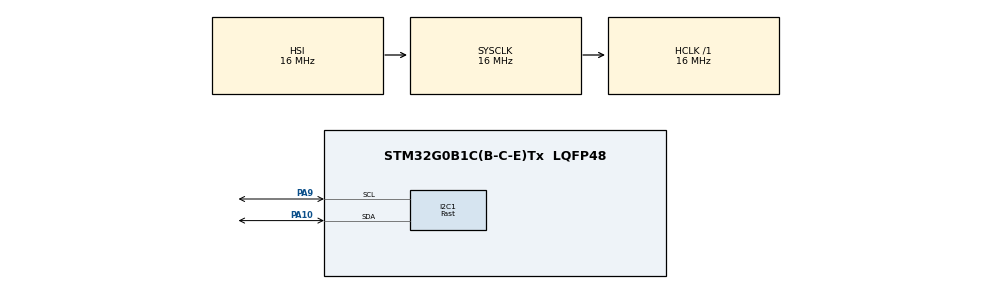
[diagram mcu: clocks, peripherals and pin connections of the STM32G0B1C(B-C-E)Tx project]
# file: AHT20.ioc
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Dma.I2C1_RX.0.Direction=DMA_PERIPH_TO_MEMORY
Dma.I2C1_RX.0.EventEnable=DISABLE
Dma.I2C1_RX.0.Instance=DMA1_Channel1
Dma.I2C1_RX.0.MemDataAlignment=DMA_MDATAALIGN_BYTE
Dma.I2C1_RX.0.MemInc=DMA_MINC_ENABLE
Dma.I2C1_RX.0.Mode=DMA_NORMAL
Dma.I2C1_RX.0.PeriphDataAlignment=DMA_PDATAALIGN_BYTE
Dma.I2C1_RX.0.PeriphInc=DMA_PINC_DISABLE
Dma.I2C1_RX.0.Polarity=HAL_DMAMUX_REQ_GEN_RISING
Dma.I2C1_RX.0.Priority=DMA_PRIORITY_LOW
Dma.I2C1_RX.0.RequestNumber=1
Dma.I2C1_RX.0.SignalID=NONE
Dma.I2C1_RX.0.SyncEnable=DISABLE
Dma.I2C1_RX.0.SyncPolarity=HAL_DMAMUX_SYNC_NO_EVENT
Dma.I2C1_RX.0.SyncRequestNumber=1
Dma.I2C1_RX.0.SyncSignalID=NONE
Dma.I2C1_TX.1.Direction=DMA_MEMORY_TO_PERIPH
Dma.I2C1_TX.1.EventEnable=DISABLE
Dma.I2C1_TX.1.Instance=DMA1_Channel2
Dma.I2C1_TX.1.MemDataAlignment=DMA_MDATAALIGN_BYTE
Dma.I2C1_TX.1.MemInc=DMA_MINC_ENABLE
Dma.I2C1_TX.1.Mode=DMA_NORMAL
Dma.I2C1_TX.1.PeriphDataAlignment=DMA_PDATAALIGN_BYTE
Dma.I2C1_TX.1.PeriphInc=DMA_PINC_DISABLE
Dma.I2C1_TX.1.Polarity=HAL_DMAMUX_REQ_GEN_RISING
Dma.I2C1_TX.1.Priority=DMA_PRIORITY_LOW
Dma.I2C1_TX.1.RequestNumber=1
Dma.I2C1_TX.1.SignalID=NONE
Dma.I2C1_TX.1.SyncEnable=DISABLE
Dma.I2C1_TX.1.SyncPolarity=HAL_DMAMUX_SYNC_NO_EVENT
Dma.I2C1_TX.1.SyncRequestNumber=1
Dma.I2C1_TX.1.SyncSignalID=NONE
Dma.Request0=I2C1_RX
Dma.Request1=I2C1_TX
FREERTOS.BinarySemaphores01=myBinarySem01,Static,myBinarySem01ControlBlock,Available
FREERTOS.Tasks01=defaultTask,24,128,StartDefaultTask,Default,NULL,Dynamic,NULL,NULL
FREERTOS.configENABLE_FPU=1
FREERTOS.configUSE_NEWLIB_REENTRANT=1
I2C1.I2C_Speed_Mode=I2C_Fast
I2C1.Timing=0x00300617
Mcu.Family=STM32G0
Mcu.Name=STM32G0B1C(B-C-E)Tx
Mcu.Package=LQFP48
NVIC.DMA1_Channel1_IRQn=true\:3\:0\:false\:false\:true\:true\:false\:true\:true
NVIC.DMA1_Channel2_3_IRQn=true\:3\:0\:false\:false\:true\:true\:false\:true\:true
NVIC.I2C1_IRQn=true\:3\:0\:false\:false\:true\:true\:true\:true\:true
PA10.GPIO_Pu=GPIO_PULLUP
PA10.Mode=I2C
PA10.Signal=I2C1_SDA
PA13.Mode=Serial_Wire
PA13.Signal=SYS_SWDIO
PA14-BOOT0.Mode=Serial_Wire
PA14-BOOT0.Signal=SYS_SWCLK
PA9.GPIO_Pu=GPIO_PULLUP
PA9.Mode=I2C
PA9.Signal=I2C1_SCL
ProjectManager.HeapSize=0x200
ProjectManager.StackSize=0x400
ProjectManager.TargetToolchain=STM32CubeIDE
RCC.AHBFreq_Value=16000000
RCC.CortexFreq_Value=16000000
RCC.EXTERNAL_CLOCK_VALUE=48000
RCC.HCLKFreq_Value=16000000
RCC.HSE_VALUE=8000000
RCC.HSI48_VALUE=48000000
RCC.HSI_VALUE=16000000
RCC.LSE_VALUE=32768
RCC.SYSCLKFreq_VALUE=16000000
RCC.USBFreq_Value=48000000
RCC.VCOOutputFreq_Value=128000000
VP_FREERTOS_VS_CMSIS_V2.Mode=CMSIS_V2
VP_SYS_VS_DBSignals.Mode=DisableDeadBatterySignals
board=custom

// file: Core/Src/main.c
/* USER CODE BEGIN Header */
/**
  ******************************************************************************
  * @file           : main.c
  * @brief          : Main program body
  ******************************************************************************
  * @attention
  *
  * Copyright (c) 2026 STMicroelectronics.
  * All rights reserved.
  *
  * This software is licensed under terms that can be found in the LICENSE file
  * in the root directory of this software component.
  * If no LICENSE file comes with this software, it is provided AS-IS.
  *
  ******************************************************************************
  */
/* USER CODE END Header */
#include "main.h"
#include "cmsis_os.h"
#include "dma.h"
#include "i2c.h"
#include "gpio.h"

void SystemClock_Config(void);
void MX_FREERTOS_Init(void);

int main(void)
{

  /* MCU Configuration--------------------------------------------------------*/

  /* Reset of all peripherals, Initializes the Flash interface and the Systick. */
  HAL_Init();

  /* Configure the system clock */
  SystemClock_Config();

  /* Initialize all configured peripherals */
  MX_GPIO_Init();
  MX_DMA_Init();
  MX_I2C1_Init();

  /* Init scheduler */
  osKernelInitialize();  /* Call init function for freertos objects (in cmsis_os2.c) */
  MX_FREERTOS_Init();

  /* Start scheduler */
  osKernelStart();

  /* We should never get here as control is now taken by the scheduler */

  /* Infinite loop */
  while (1)
  {

  }
}

void SystemClock_Config(void)
{
  RCC_OscInitTypeDef RCC_OscInitStruct = {0};
  RCC_ClkInitTypeDef RCC_ClkInitStruct = {0};

  /** Configure the main internal regulator output voltage
  */
  HAL_PWREx_ControlVoltageScaling(PWR_REGULATOR_VOLTAGE_SCALE1);

  /** Initializes the RCC Oscillators according to the specified parameters
  * in the RCC_OscInitTypeDef structure.
  */
  RCC_OscInitStruct.OscillatorType = RCC_OSCILLATORTYPE_HSI;
  RCC_OscInitStruct.HSIState = RCC_HSI_ON;
  RCC_OscInitStruct.HSIDiv = RCC_HSI_DIV1;
  RCC_OscInitStruct.HSICalibrationValue = RCC_HSICALIBRATION_DEFAULT;
  RCC_OscInitStruct.PLL.PLLState = RCC_PLL_NONE;
  if (HAL_RCC_OscConfig(&RCC_OscInitStruct) != HAL_OK)
  {
    Error_Handler();
  }

  /** Initializes the CPU, AHB and APB buses clocks
  */
  RCC_ClkInitStruct.ClockType = RCC_CLOCKTYPE_HCLK|RCC_CLOCKTYPE_SYSCLK
                              |RCC_CLOCKTYPE_PCLK1;
  RCC_ClkInitStruct.SYSCLKSource = RCC_SYSCLKSOURCE_HSI;
  RCC_ClkInitStruct.AHBCLKDivider = RCC_SYSCLK_DIV1;
  RCC_ClkInitStruct.APB1CLKDivider = RCC_HCLK_DIV1;

  if (HAL_RCC_ClockConfig(&RCC_ClkInitStruct, FLASH_LATENCY_0) != HAL_OK)
  {
    Error_Handler();
  }
}

void Error_Handler(void)
{
  __disable_irq();
  while (1)
  {
  }
}

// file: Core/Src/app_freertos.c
/* USER CODE BEGIN Header */
/**
  ******************************************************************************
  * File Name          : app_freertos.c
  * Description        : Code for freertos applications
  ******************************************************************************
  * @attention
  *
  * Copyright (c) 2026 STMicroelectronics.
  * All rights reserved.
  *
  * This software is licensed under terms that can be found in the LICENSE file
  * in the root directory of this software component.
  * If no LICENSE file comes with this software, it is provided AS-IS.
  *
  ******************************************************************************
  */
/* USER CODE END Header */

#include "FreeRTOS.h"
#include "task.h"
#include "main.h"
#include "cmsis_os.h"

/* USER CODE BEGIN Includes */
#include "aht20.h"
#include "i2c.h"
/* USER CODE END Includes */

typedef StaticSemaphore_t osStaticSemaphoreDef_t;

/* Definitions for defaultTask */
osThreadId_t defaultTaskHandle;
const osThreadAttr_t defaultTask_attributes = {
  .name = "defaultTask",
  .priority = (osPriority_t) osPriorityNormal,
  .stack_size = 128 * 4
};
/* Definitions for myBinarySem01 */
osSemaphoreId_t myBinarySem01Handle;
osStaticSemaphoreDef_t myBinarySem01ControlBlock;
const osSemaphoreAttr_t myBinarySem01_attributes = {
  .name = "myBinarySem01",
  .cb_mem = &myBinarySem01ControlBlock,
  .cb_size = sizeof(myBinarySem01ControlBlock),
};

void StartDefaultTask(void *argument);

void MX_FREERTOS_Init(void); /* (MISRA C 2004 rule 8.1) */

void MX_FREERTOS_Init(void) {

  /* Create the semaphores(s) */
  /* creation of myBinarySem01 */
  myBinarySem01Handle = osSemaphoreNew(1, 1, &myBinarySem01_attributes);

  /* Create the thread(s) */
  /* creation of defaultTask */
  defaultTaskHandle = osThreadNew(StartDefaultTask, NULL, &defaultTask_attributes);

}

/* USER CODE BEGIN Header_StartDefaultTask */
/**
  * @brief  Function implementing the defaultTask thread.
  * @param  argument: Not used
  * @retval None
  */

AHT20_HandleTypeDef aht20;
/* USER CODE END Header_StartDefaultTask */
void StartDefaultTask(void *argument)
{
  /* USER CODE BEGIN StartDefaultTask */
  aht20.hi2c = &hi2c1;
  aht20.i2cSemaphore = myBinarySem01Handle;
  AHT20_Setup();
  AHT20_Init();
  /* Infinite loop */
  for(;;)
  {
	AHT20_Measure();
  }
  /* USER CODE END StartDefaultTask */
}

/* USER CODE BEGIN Application */
void HAL_I2C_MasterTxCpltCallback(I2C_HandleTypeDef *hi2c) {
	if (hi2c->Instance == aht20.hi2c->Instance) {
		AHT20_ReleaseSemaphore();
	}
}

void HAL_I2C_MasterRxCpltCallback(I2C_HandleTypeDef *hi2c) {
	if (hi2c->Instance == aht20.hi2c->Instance) {
		AHT20_ReleaseSemaphore();
	}
}
/* USER CODE END Application */
